# ESP32-H4 register map
Vendor: ESPRESSIF SYSTEMS (SHANGHAI) CO., LTD.; Series: ESP32 H-Series; File version: 1
CPU: RV32IMAC r0p0, little endian, no MPU, no FPU, 0 interrupt priority bits
Address unit: 32 bits
Registers are 32-bit, read-write, reset 0x0 unless marked. A register's access mark holds for its fields unless they carry their own. Offsets are from the block's base; [hi:lo] are bit positions; {n}, {i} and the like mark numbered series.

## GPIO — General Purpose Input/Output
Base 0x60093000
0x00 STRAP ro — Strapping pin register
  [15:0] STRAPPING — Represents the values of GPIO strapping pins. (need update the description, for example) - bit0: invalid - bit1: MTMS - bit2: MTDI - bit3: GPIO27 - bit4: GPIO28 - bit5: GPIO7 - bit6 ~ bit15: invalid
0x04 OUT — GPIO output register
  [31:0] DATA_ORIG — Configures the output value of GPIO0 ~ 31 output in simple GPIO output mode.\\ 0: Low level\\ 1: High level\\ The value of bit0 ~ bit31 correspond to the output value of GPIO0 ~ GPIO31 respectively. Bitxx ~ bitxx is invalid.\\
0x08 OUT_W1TS wo — GPIO output set register
  [31:0] OUT_W1TS — Configures whether or not to set the output register GPIO_OUT_REG of GPIO0 ~ GPIO31.\\ 0: Not set\\ 1: The corresponding bit in GPIO_OUT_REG will be set to 1\\ Bit0 ~ bit31 are corresponding to GPIO0 ~ GPIO31. Bitxx ~ bitxx is invalid. \\ Recommended operation: use this register to set GPIO_OUT_REG. \\
0x0C OUT_W1TC wo — GPIO output clear register
  [31:0] OUT_W1TC — Configures whether or not to clear the output register GPIO_OUT_REG of GPIO0 ~ GPIO31 output.\\ 0: Not clear\\ 1: The corresponding bit in GPIO_OUT_REG will be cleared.\\ Bit0 ~ bit31 are corresponding to GPIO0 ~ GPIO31. Bitxx ~ bitxx is invalid. \\ Recommended operation: use this register to clear GPIO_OUT_REG. \\
0x10 OUT1 — GPIO output register
  [11:0] DATA_ORIG — Configures the output value of GPIO32 ~ 43 output in simple GPIO output mode.\\ 0: Low level\\ 1: High level\\ The value of bit32 ~ bit43 correspond to the output value of GPIO32 ~ GPIO43 respectively. Bitxx ~ bitxx is invalid.\\
0x14 OUT1_W1TS wo — GPIO output set register
  [11:0] OUT1_W1TS — Configures whether or not to set the output register GPIO_OUT1_REG of GPIO32 ~ GPIO43.\\ 0: Not set\\ 1: The corresponding bit in GPIO_OUT1_REG will be set to 1\\ Bit32 ~ bit43 are corresponding to GPIO32 ~ GPIO43. Bitxx ~ bitxx is invalid. \\ Recommended operation: use this register to set GPIO_OUT1_REG. \\
0x18 OUT1_W1TC wo — GPIO output clear register
  [11:0] OUT1_W1TC — Configures whether or not to clear the output register GPIO_OUT1_REG of GPIO32 ~ GPIO43 output.\\ 0: Not clear\\ 1: The corresponding bit in GPIO_OUT1_REG will be cleared.\\ Bit32 ~ bit43 are corresponding to GPIO32 ~ GPIO43. Bitxx ~ bitxx is invalid. \\ Recommended operation: use this register to clear GPIO_OUT1_REG. \\
0x34 ENABLE — GPIO output enable register
  [31:0] DATA — Configures whether or not to enable the output of GPIO0 ~ GPIO31.\\ 0: Not enable\\ 1: Enable\\ Bit0 ~ bit31 are corresponding to GPIO0 ~ GPIO31. Bitxx ~ bitxx is invalid.\\
0x38 ENABLE_W1TS wo — GPIO output enable set register
  [31:0] ENABLE_W1TS — Configures whether or not to set the output enable register GPIO_ENABLE_REG of GPIO0 ~ GPIO31.\\ 0: Not set\\ 1: The corresponding bit in GPIO_ENABLE_REG will be set to 1\\ Bit0 ~ bit31 are corresponding to GPIO0 ~ GPIO31. Bitxx ~ bitxx is invalid. \\ Recommended operation: use this register to set GPIO_ENABLE_REG.\\
0x3C ENABLE_W1TC wo — GPIO output enable clear register
  [31:0] ENABLE_W1TC — Configures whether or not to clear the output enable register GPIO_ENABLE_REG of GPIO0 ~ GPIO31. \\ 0: Not clear\\ 1: The corresponding bit in GPIO_ENABLE_REG will be cleared\\ Bit0 ~ bit31 are corresponding to GPIO0 ~ GPIO31. Bitxx ~ bitxx is invalid. \\ Recommended operation: use this register to clear GPIO_ENABLE_REG.\\
0x40 ENABLE1 — GPIO output enable register
  [11:0] DATA — Configures whether or not to enable the output of GPIO32 ~ GPIO43.\\ 0: Not enable\\ 1: Enable\\ Bit32 ~ bit43 are corresponding to GPIO32 ~ GPIO43. Bitxx ~ bitxx is invalid.\\
0x44 ENABLE1_W1TS wo — GPIO output enable set register
  [11:0] ENABLE1_W1TS — Configures whether or not to set the output enable register GPIO_ENABLE1_REG of GPIO32 ~ GPIO43.\\ 0: Not set\\ 1: The corresponding bit in GPIO_ENABLE1_REG will be set to 1\\ Bit32 ~ bit43 are corresponding to GPIO32 ~ GPIO43. Bitxx ~ bitxx is invalid. \\ Recommended operation: use this register to set GPIO_ENABLE1_REG.\\
0x48 ENABLE1_W1TC wo — GPIO output enable clear register
  [11:0] ENABLE1_W1TC — Configures whether or not to clear the output enable register GPIO_ENABLE1_REG of GPIO32 ~ GPIO43. \\ 0: Not clear\\ 1: The corresponding bit in GPIO_ENABLE1_REG will be cleared\\ Bit32 ~ bit43 are corresponding to GPIO32 ~ GPIO43. Bitxx ~ bitxx is invalid. \\ Recommended operation: use this register to clear GPIO_ENABLE1_REG.\\
0x64 IN ro — GPIO input register
  [31:0] DATA_NEXT — Represents the input value of GPIO0 ~ GPIO31. Each bit represents a pin input value:\\ 0: Low level\\ 1: High level\\ Bit0 ~ bit31 are corresponding to GPIO0 ~ GPIO31. Bitxx ~ bitxx is invalid.\\
0x68 IN1 ro — GPIO input register
  [11:0] DATA_NEXT — Represents the input value of GPIO32 ~ GPIO43. Each bit represents a pin input value:\\ 0: Low level\\ 1: High level\\ Bit32 ~ bit43 are corresponding to GPIO32 ~ GPIO43. Bitxx ~ bitxx is invalid.\\
0x74 STATUS — GPIO interrupt status register
  [31:0] INTERRUPT — The interrupt status of GPIO0 ~ GPIO31, can be configured by the software. - Bit0 ~ bit31 are corresponding to GPIO0 ~ GPIO31. Bitxx ~ bitxx is invalid. - Each bit represents the status of its corresponding GPIO: - 0: Represents the GPIO does not generate the interrupt configured by GPIO_PIN0_INT_TYPE, or this bit is configured to 0 by the software. - 1: Represents the GPIO generates the interrupt configured by GPIO_PIN0_INT_TYPE, or this bit is configured to 1 by the software.
0x78 STATUS_W1TS wo — GPIO interrupt status set register
  [31:0] STATUS_W1TS — Configures whether or not to set the interrupt status register GPIO_STATUS_INTERRUPT of GPIO0 ~ GPIO31. - Bit0 ~ bit31 are corresponding to GPIO0 ~ GPIO31. Bitxx ~ bitxx is invalid. - If the value 1 is written to a bit here, the corresponding bit in GPIO_STATUS_INTERRUPT will be set to 1. \item Recommended operation: use this register to set GPIO_STATUS_INTERRUPT.
0x7C STATUS_W1TC wo — GPIO interrupt status clear register
  [31:0] STATUS_W1TC — Configures whether or not to clear the interrupt status register GPIO_STATUS_INTERRUPT of GPIO0 ~ GPIO31. - Bit0 ~ bit31 are corresponding to GPIO0 ~ GPIO31. Bitxx ~ bitxx is invalid. - If the value 1 is written to a bit here, the corresponding bit in GPIO_STATUS_INTERRUPT will be cleared. \item Recommended operation: use this register to clear GPIO_STATUS_INTERRUPT.
0x80 STATUS1 — GPIO interrupt status register
  [11:0] INTERRUPT — The interrupt status of GPIO32 ~ GPIO43, can be configured by the software. - Bit32 ~ bit43 are corresponding to GPIO32 ~ GPIO43. Bitxx ~ bitxx is invalid. - Each bit represents the status of its corresponding GPIO: - 0: Represents the GPIO does not generate the interrupt configured by GPIO_PIN0_INT_TYPE, or this bit is configured to 0 by the software. - 1: Represents the GPIO generates the interrupt configured by GPIO_PIN0_INT_TYPE, or this bit is configured to 1 by the software.
0x84 STATUS1_W1TS wo — GPIO interrupt status set register
  [11:0] STATUS1_W1TS — Configures whether or not to set the interrupt status register GPIO_STATUS1_INTERRUPT of GPIO32 ~ GPIO43. - Bit32 ~ bit43 are corresponding to GPIO32 ~ GPIO43. Bitxx ~ bitxx is invalid. - If the value 1 is written to a bit here, the corresponding bit in GPIO_STATUS1_INTERRUPT will be set to 1. \item Recommended operation: use this register to set GPIO_STATUS1_INTERRUPT.
0x88 STATUS1_W1TC wo — GPIO interrupt status clear register
  [11:0] STATUS1_W1TC — Configures whether or not to clear the interrupt status register GPIO_STATUS1_INTERRUPT of GPIO32 ~ GPIO43. - Bit32 ~ bit43 are corresponding to GPIO32 ~ GPIO43. Bitxx ~ bitxx is invalid. - If the value 1 is written to a bit here, the corresponding bit in GPIO_STATUS1_INTERRUPT will be cleared. \item Recommended operation: use this register to clear GPIO_STATUS1_INTERRUPT.
0xA4 INTR_0 ro — GPIO_PROCPU_INT interrupt status register
  [31:0] INTR_0 — Represents the GPIO_PROCPU_INT interrupt status of GPIO0 ~ GPIO31. Each bit represents:(need update in different project)\\ 0: Represents GPIO_PROCPU_INT interrupt is not enabled, or the GPIO does not generate the interrupt configured by GPIO_PIN0_INT_TYPE.\\ 1: Represents the GPIO generates an interrupt configured by GPIO_PIN0_INT_TYPE after the GPIO_PROCPU_INT interrupt is enabled.\\ Bit0 ~ bit31 are corresponding to GPIO0 ~ GPIO31. Bitxx ~ bitxx is invalid. This interrupt status is corresponding to the bit in GPIO_STATUS_REG when assert (high) enable signal (bit13 of GPIO_PIN0_REG). \\
0xA8 INTR_1 ro — GPIO_INTERRUPT_2 interrupt status register
  [31:0] INTR_1 — Represents the GPIO_INTERRUPT_2 interrupt status of GPIO0 ~ GPIO31. Each bit represents:(need update in different project)\\ 0: Represents GPIO_INTERRUPT_2 interrupt is not enabled, or the GPIO does not generate the interrupt configured by GPIO_PIN0_INT_TYPE.\\ 1: Represents the GPIO generates an interrupt configured by GPIO_PIN0_INT_TYPE after the GPIO_INTERRUPT_2 interrupt is enabled.\\ Bit0 ~ bit31 are corresponding to GPIO0 ~ GPIO31. Bitxx ~ bitxx is invalid. This interrupt status is corresponding to the bit in GPIO_STATUS_REG when assert (high) enable signal (bit13 of GPIO_PIN0_REG). \\
0xAC INTR1_0 ro — GPIO_PROCPU_INT interrupt status register
  [11:0] INTR1_0 — Represents the GPIO_PROCPU_INT interrupt status of GPIO32 ~ GPIO43. Each bit represents:(need update in different project)\\ 0: Represents GPIO_PROCPU_INT interrupt is not enabled, or the GPIO does not generate the interrupt configured by GPIO_PIN0_INT_TYPE.\\ 1: Represents the GPIO generates an interrupt configured by GPIO_PIN0_INT_TYPE after the GPIO_PROCPU_INT interrupt is enabled.\\ Bit32 ~ bit43 are corresponding to GPIO32 ~ GPIO43. Bitxx ~ bitxx is invalid. This interrupt status is corresponding to the bit in GPIO_STATUS1_REG when assert (high) enable signal (bit13 of GPIO_PIN0_REG). \\
0xB0 INTR1_1 ro — GPIO_INTERRUPT_2 interrupt status register
  [11:0] INTR1_1 — Represents the GPIO_INTERRUPT_2 interrupt status of GPIO32 ~ GPIO43. Each bit represents:(need update in different project)\\ 0: Represents GPIO_INTERRUPT_2 interrupt is not enabled, or the GPIO does not generate the interrupt configured by GPIO_PIN0_INT_TYPE.\\ 1: Represents the GPIO generates an interrupt configured by GPIO_PIN0_INT_TYPE after the GPIO_INTERRUPT_2 interrupt is enabled.\\ Bit32 ~ bit43 are corresponding to GPIO32 ~ GPIO43. Bitxx ~ bitxx is invalid. This interrupt status is corresponding to the bit in GPIO_STATUS1_REG when assert (high) enable signal (bit13 of GPIO_PIN0_REG). \\
0xC4 STATUS_NEXT ro — GPIO interrupt source register
  [31:0] STATUS_INTERRUPT_NEXT — Represents the interrupt source signal of GPIO0 ~ GPIO31.\\ Bit0 ~ bit24 are corresponding to GPIO0 ~ GPIO31. Bitxx ~ bitxx is invalid. Each bit represents:\\ 0: The GPIO does not generate the interrupt configured by GPIO_PIN0_INT_TYPE.\\ 1: The GPIO generates an interrupt configured by GPIO_PIN0_INT_TYPE.\\ The interrupt could be rising edge interrupt, falling edge interrupt, level sensitive interrupt and any edge interrupt.\\
0xC8 STATUS_NEXT1 ro — GPIO interrupt source register
  [11:0] STATUS_INTERRUPT_NEXT1 — Represents the interrupt source signal of GPIO32 ~ GPIO43.\\ Bit0 ~ bit24 are corresponding to GPIO32 ~ GPIO43. Bitxx ~ bitxx is invalid. Each bit represents:\\ 0: The GPIO does not generate the interrupt configured by GPIO_PIN0_INT_TYPE.\\ 1: The GPIO generates an interrupt configured by GPIO_PIN0_INT_TYPE.\\ The interrupt could be rising edge interrupt, falling edge interrupt, level sensitive interrupt and any edge interrupt.\\
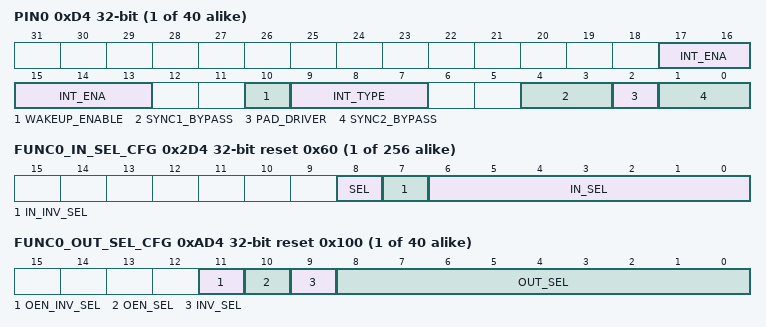
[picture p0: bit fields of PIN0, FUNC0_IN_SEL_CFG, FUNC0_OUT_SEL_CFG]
{0xD4+4i} PIN{i} (i=0..39) — GPIO{i} configuration register
  [17:13] INT_ENA — Configures whether or not to enable gpio_procpu_int or gpio_interrupt_2(need update in different project). - bit13: Configures whether or not to enable gpio_procpu_int(need update in different project):\\ 0: Disable\\ 1: Enable\\ - bit14: Configures whether or not to enable gpio_interrupt_2(need update in different project):\\ 0: Disable\\ 1: Enable\\ - bit15 ~ bit17: invalid
  [10] WAKEUP_ENABLE — Configures whether or not to enable GPIO wake-up function.\\ 0: Disable\\ 1: Enable\\ This function only wakes up the CPU from Light-sleep. \\
  [9:7] INT_TYPE — Configures GPIO interrupt type.\\ 0: GPIO interrupt disabled\\ 1: Rising edge trigger\\ 2: Falling edge trigger\\ 3: Any edge trigger\\ 4: Low level trigger\\ 5: High level trigger\\
  [4:3] SYNC1_BYPASS — Configures whether or not to synchronize GPIO input data on either edge of IO MUX operating clock for the first-level synchronization.\\ 0: Not synchronize\\ 1: Synchronize on falling edge\\ 2: Synchronize on rising edge\\ 3: Synchronize on rising edge\\
  [2] PAD_DRIVER — Configures to select pin drive mode. \\ 0: Normal output\\ 1: Open drain output \\
  [1:0] SYNC2_BYPASS — Configures whether or not to synchronize GPIO input data on either edge of IO MUX operating clock for the second-level synchronization.\\ 0: Not synchronize\\ 1: Synchronize on falling edge\\ 2: Synchronize on rising edge\\ 3: Synchronize on rising edge\\
{0x2D4+4i} FUNC{i}_IN_SEL_CFG (i=0..255) reset 0x60 — GPIO input function configuration register
  [8] SEL — Bypass GPIO matrix. 0: bypass. 1: route via GPIO matrix.
  [7] IN_INV_SEL — Invert the input value. 0: not invert. 1: invert.
  [6:0] IN_SEL — Select a pin for input signal %s.
{0xAD4+4i} FUNC{i}_OUT_SEL_CFG (i=0..39) reset 0x100 — GPIO output function configuration register
  [11] OEN_INV_SEL — Invert the output-enable signal.
  [10] OEN_SEL — Select output-enable source.
  [9] INV_SEL — Invert the output value.
  [8:0] OUT_SEL — Select a peripheral signal for GPIO%s output.
0xDF8 CLOCK_GATE reset 0x1 — GPIO clock gate register
  [0] CLK_EN — Configures whether or not to enable clock gate.\\ 0: Not enable\\ 1: Enable, the clock is free running. \\
0xDFC DATE — GPIO version register

## Notices in the file
Copyright 2026 Espressif Systems (Shanghai) PTE LTD
Licensed under the Apache License, Version 2.0 (the "License");
you may not use this file except in compliance with the License.
You may obtain a copy of the License at
http://www.apache.org/licenses/LICENSE-2.0
Unless required by applicable law or agreed to in writing, software
distributed under the License is distributed on an "AS IS" BASIS,
WITHOUT WARRANTIES OR CONDITIONS OF ANY KIND, either express or implied.
See the License for the specific language governing permissions and
limitations under the License.
